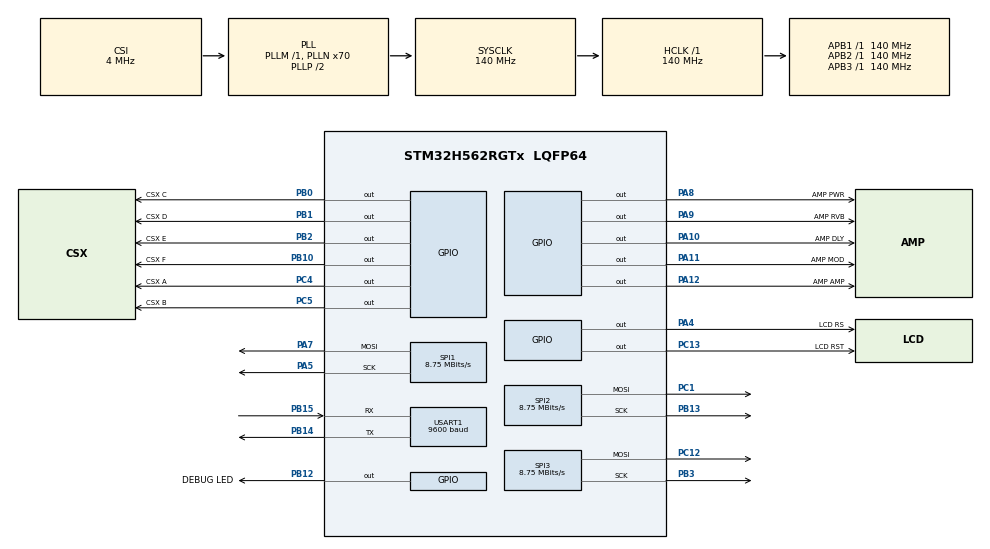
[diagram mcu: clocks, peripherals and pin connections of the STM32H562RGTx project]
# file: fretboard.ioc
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BOOTPATH.BootPathName=LEGACY
BOOTPATH.UserSelectedBootPath=LEGACY
CORTEX_M33_NS.userName=CORTEX_M33
Mcu.Family=STM32H5
Mcu.Name=STM32H562RGTx
Mcu.Package=LQFP64
NVIC.PriorityGroup=NVIC_PRIORITYGROUP_4
NVIC.TIM6_IRQn=true\:1\:0\:true\:false\:true\:true\:true\:true
NVIC.USART1_IRQn=true\:0\:0\:false\:false\:true\:true\:true\:true
PA10.GPIO_Label=AMP DLY
PA10.Signal=GPIO_Output
PA11.GPIO_Label=AMP MOD
PA11.Signal=GPIO_Output
PA12.GPIO_Label=AMP AMP
PA12.Signal=GPIO_Output
PA13(JTMS/SWDIO).Mode=Serial_Wire
PA13(JTMS/SWDIO).Signal=DEBUG_JTMS-SWDIO
PA14(JTCK/SWCLK).Mode=Serial_Wire
PA14(JTCK/SWCLK).Signal=DEBUG_JTCK-SWCLK
PA4.GPIO_Label=LCD RS
PA4.Signal=GPIO_Output
PA5.Mode=TX_Only_Simplex_Unidirect_Master
PA5.Signal=SPI1_SCK
PA7.Mode=TX_Only_Simplex_Unidirect_Master
PA7.Signal=SPI1_MOSI
PA8.GPIO_Label=AMP PWR
PA8.Signal=GPIO_Output
PA9.GPIO_Label=AMP RVB
PA9.Signal=GPIO_Output
PB0.GPIO_Label=CSX C
PB0.Signal=GPIO_Output
PB1.GPIO_Label=CSX D
PB1.Signal=GPIO_Output
PB10.GPIO_Label=CSX F
PB10.Signal=GPIO_Output
PB12.GPIO_Label=DEBUG LED
PB12.Signal=GPIO_Output
PB13.Mode=TX_Only_Simplex_Unidirect_Master
PB13.Signal=SPI2_SCK
PB14.Mode=Asynchronous
PB14.Signal=USART1_TX
PB15.Mode=Asynchronous
PB15.Signal=USART1_RX
PB2.GPIO_Label=CSX E
PB2.Signal=GPIO_Output
PB3(JTDO/TRACESWO).Mode=TX_Only_Simplex_Unidirect_Master
PB3(JTDO/TRACESWO).Signal=SPI3_SCK
PC1.Mode=TX_Only_Simplex_Unidirect_Master
PC1.Signal=SPI2_MOSI
PC12.Mode=TX_Only_Simplex_Unidirect_Master
PC12.Signal=SPI3_MOSI
PC13.GPIO_Label=LCD RST
PC13.Signal=GPIO_Output
PC4.GPIO_Label=CSX A
PC4.Signal=GPIO_Output
PC5.GPIO_Label=CSX B
PC5.Signal=GPIO_Output
ProjectManager.HeapSize=0x200
ProjectManager.StackSize=0x400
ProjectManager.TargetToolchain=STM32CubeIDE
RCC.ADCFreq_Value=140000000
RCC.AHBFreq_Value=140000000
RCC.APB1Freq_Value=140000000
RCC.APB1TimFreq_Value=140000000
RCC.APB2Freq_Value=140000000
RCC.APB2TimFreq_Value=140000000
RCC.APB3Freq_Value=140000000
RCC.CSI_VALUE=4000000
RCC.CortexFreq_Value=140000000
RCC.EPOD_VALUE=4000000
RCC.HCLKFreq_Value=140000000
RCC.HSE_VALUE=25000000
RCC.HSI48_VALUE=48000000
RCC.HSI_VALUE=64000000
RCC.LSE_VALUE=32768
RCC.LSIRC_VALUE=32000
RCC.PLL2FRACN=0
RCC.PLL3FRACN=0
RCC.PLLFRACN=0
RCC.PLLN=70
RCC.SYSCLKFreq_VALUE=140000000
RCC.SYSCLKSource=RCC_SYSCLKSOURCE_PLLCLK
RCC.USBFreq_Value=48000000
RCC.VCOOutputFreq_Value=280000000
SPI1.BaudRatePrescaler=SPI_BAUDRATEPRESCALER_16
SPI1.CalculateBaudRate=8.75 MBits/s
SPI1.DataSize=SPI_DATASIZE_8BIT
SPI1.Direction=SPI_DIRECTION_2LINES_TXONLY
SPI1.Mode=SPI_MODE_MASTER
SPI1.VirtualType=VM_MASTER
SPI2.BaudRatePrescaler=SPI_BAUDRATEPRESCALER_16
SPI2.CalculateBaudRate=8.75 MBits/s
SPI2.DataSize=SPI_DATASIZE_8BIT
SPI2.Direction=SPI_DIRECTION_2LINES_TXONLY
SPI2.Mode=SPI_MODE_MASTER
SPI2.VirtualType=VM_MASTER
SPI3.BaudRatePrescaler=SPI_BAUDRATEPRESCALER_16
SPI3.CalculateBaudRate=8.75 MBits/s
SPI3.DataSize=SPI_DATASIZE_8BIT
SPI3.Direction=SPI_DIRECTION_2LINES_TXONLY
SPI3.Mode=SPI_MODE_MASTER
SPI3.VirtualType=VM_MASTER
TIM6.PeriodNoDither=9
TIM6.Prescaler=24999
USART1.BaudRate=9600
USART1.OverrunDisableParam=ADVFEATURE_OVERRUN_ENABLE
USART1.VirtualMode-Asynchronous=VM_ASYNC
VP_BOOTPATH_VS_BOOTPATH.Mode=BP_Activate
VP_CORTEX_M33_NS_VS_Hclk.Mode=Hclk_Mode
VP_ICACHE_VS_ICACHE.Mode=DirectMappedCache
VP_MEMORYMAP_VS_MEMORYMAP.Mode=CurAppReg
VP_PWR_VS_DBSignals.Mode=DisableDeadBatterySignals
VP_PWR_VS_LPOM.Mode=PowerOptimisation
VP_PWR_VS_SECSignals.Mode=Security/Privilege
VP_TIM6_VS_ClockSourceINT.Mode=Enable_Timer
board=custom

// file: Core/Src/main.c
/* USER CODE BEGIN Header */
/**
  ******************************************************************************
  * @file           : main.c
  * @brief          : Main program body
  ******************************************************************************
  * @attention
  *
  * Copyright (c) 2024 STMicroelectronics.
  * All rights reserved.
  *
  * This software is licensed under terms that can be found in the LICENSE file
  * in the root directory of this software component.
  * If no LICENSE file comes with this software, it is provided AS-IS.
  *
  ******************************************************************************
  */
/* USER CODE END Header */
#include "main.h"

SPI_HandleTypeDef hspi1;
SPI_HandleTypeDef hspi2;
SPI_HandleTypeDef hspi3;

TIM_HandleTypeDef htim6;

UART_HandleTypeDef huart1;

void SystemClock_Config(void);
static void MX_GPIO_Init(void);
static void MX_SPI1_Init(void);
static void MX_USART1_UART_Init(void);
static void MX_SPI2_Init(void);
static void MX_TIM6_Init(void);
static void MX_SPI3_Init(void);
static void MX_ICACHE_Init(void);

int main(void)
{

  /* MCU Configuration--------------------------------------------------------*/

  /* Reset of all peripherals, Initializes the Flash interface and the Systick. */
  HAL_Init();

  /* Configure the system clock */
  SystemClock_Config();

  /* Initialize all configured peripherals */
  MX_GPIO_Init();
  MX_SPI1_Init();
  MX_USART1_UART_Init();
  MX_SPI2_Init();
  MX_TIM6_Init();
  MX_SPI3_Init();
  MX_ICACHE_Init();
  /* USER CODE BEGIN 2 */
  HAL_Post_Init();

  /* USER CODE END 2 */

  /* Infinite loop */
  while (1)
  {

  }
}

void SystemClock_Config(void)
{
  RCC_OscInitTypeDef RCC_OscInitStruct = {0};
  RCC_ClkInitTypeDef RCC_ClkInitStruct = {0};

  /** Configure the main internal regulator output voltage
  */
  __HAL_PWR_VOLTAGESCALING_CONFIG(PWR_REGULATOR_VOLTAGE_SCALE2);

  while(!__HAL_PWR_GET_FLAG(PWR_FLAG_VOSRDY)) {}

  /** Initializes the RCC Oscillators according to the specified parameters
  * in the RCC_OscInitTypeDef structure.
  */
  RCC_OscInitStruct.OscillatorType = RCC_OSCILLATORTYPE_CSI;
  RCC_OscInitStruct.CSIState = RCC_CSI_ON;
  RCC_OscInitStruct.CSICalibrationValue = RCC_CSICALIBRATION_DEFAULT;
  RCC_OscInitStruct.PLL.PLLState = RCC_PLL_ON;
  RCC_OscInitStruct.PLL.PLLSource = RCC_PLL1_SOURCE_CSI;
  RCC_OscInitStruct.PLL.PLLM = 1;
  RCC_OscInitStruct.PLL.PLLN = 70;
  RCC_OscInitStruct.PLL.PLLP = 2;
  RCC_OscInitStruct.PLL.PLLQ = 2;
  RCC_OscInitStruct.PLL.PLLR = 2;
  RCC_OscInitStruct.PLL.PLLRGE = RCC_PLL1_VCIRANGE_2;
  RCC_OscInitStruct.PLL.PLLVCOSEL = RCC_PLL1_VCORANGE_WIDE;
  RCC_OscInitStruct.PLL.PLLFRACN = 0;
  if (HAL_RCC_OscConfig(&RCC_OscInitStruct) != HAL_OK)
  {
    Error_Handler();
  }

  /** Initializes the CPU, AHB and APB buses clocks
  */
  RCC_ClkInitStruct.ClockType = RCC_CLOCKTYPE_HCLK|RCC_CLOCKTYPE_SYSCLK
                              |RCC_CLOCKTYPE_PCLK1|RCC_CLOCKTYPE_PCLK2
                              |RCC_CLOCKTYPE_PCLK3;
  RCC_ClkInitStruct.SYSCLKSource = RCC_SYSCLKSOURCE_PLLCLK;
  RCC_ClkInitStruct.AHBCLKDivider = RCC_SYSCLK_DIV1;
  RCC_ClkInitStruct.APB1CLKDivider = RCC_HCLK_DIV1;
  RCC_ClkInitStruct.APB2CLKDivider = RCC_HCLK_DIV1;
  RCC_ClkInitStruct.APB3CLKDivider = RCC_HCLK_DIV1;

  if (HAL_RCC_ClockConfig(&RCC_ClkInitStruct, FLASH_LATENCY_4) != HAL_OK)
  {
    Error_Handler();
  }

  /** Configure the programming delay
  */
  __HAL_FLASH_SET_PROGRAM_DELAY(FLASH_PROGRAMMING_DELAY_2);
}

static void MX_ICACHE_Init(void)
{

  /** Enable instruction cache in 1-way (direct mapped cache)
  */
  if (HAL_ICACHE_ConfigAssociativityMode(ICACHE_1WAY) != HAL_OK)
  {
    Error_Handler();
  }
  if (HAL_ICACHE_Enable() != HAL_OK)
  {
    Error_Handler();
  }

}

static void MX_SPI1_Init(void)
{

  /* SPI1 parameter configuration*/
  hspi1.Instance = SPI1;
  hspi1.Init.Mode = SPI_MODE_MASTER;
  hspi1.Init.Direction = SPI_DIRECTION_2LINES_TXONLY;
  hspi1.Init.DataSize = SPI_DATASIZE_8BIT;
  hspi1.Init.CLKPolarity = SPI_POLARITY_LOW;
  hspi1.Init.CLKPhase = SPI_PHASE_1EDGE;
  hspi1.Init.NSS = SPI_NSS_SOFT;
  hspi1.Init.BaudRatePrescaler = SPI_BAUDRATEPRESCALER_16;
  hspi1.Init.FirstBit = SPI_FIRSTBIT_MSB;
  hspi1.Init.TIMode = SPI_TIMODE_DISABLE;
  hspi1.Init.CRCCalculation = SPI_CRCCALCULATION_DISABLE;
  hspi1.Init.CRCPolynomial = 0x7;
  hspi1.Init.NSSPMode = SPI_NSS_PULSE_ENABLE;
  hspi1.Init.NSSPolarity = SPI_NSS_POLARITY_LOW;
  hspi1.Init.FifoThreshold = SPI_FIFO_THRESHOLD_01DATA;
  hspi1.Init.MasterSSIdleness = SPI_MASTER_SS_IDLENESS_00CYCLE;
  hspi1.Init.MasterInterDataIdleness = SPI_MASTER_INTERDATA_IDLENESS_00CYCLE;
  hspi1.Init.MasterReceiverAutoSusp = SPI_MASTER_RX_AUTOSUSP_DISABLE;
  hspi1.Init.MasterKeepIOState = SPI_MASTER_KEEP_IO_STATE_DISABLE;
  hspi1.Init.IOSwap = SPI_IO_SWAP_DISABLE;
  hspi1.Init.ReadyMasterManagement = SPI_RDY_MASTER_MANAGEMENT_INTERNALLY;
  hspi1.Init.ReadyPolarity = SPI_RDY_POLARITY_HIGH;
  if (HAL_SPI_Init(&hspi1) != HAL_OK)
  {
    Error_Handler();
  }

}

static void MX_SPI2_Init(void)
{

  /* SPI2 parameter configuration*/
  hspi2.Instance = SPI2;
  hspi2.Init.Mode = SPI_MODE_MASTER;
  hspi2.Init.Direction = SPI_DIRECTION_2LINES_TXONLY;
  hspi2.Init.DataSize = SPI_DATASIZE_8BIT;
  hspi2.Init.CLKPolarity = SPI_POLARITY_LOW;
  hspi2.Init.CLKPhase = SPI_PHASE_1EDGE;
  hspi2.Init.NSS = SPI_NSS_SOFT;
  hspi2.Init.BaudRatePrescaler = SPI_BAUDRATEPRESCALER_16;
  hspi2.Init.FirstBit = SPI_FIRSTBIT_MSB;
  hspi2.Init.TIMode = SPI_TIMODE_DISABLE;
  hspi2.Init.CRCCalculation = SPI_CRCCALCULATION_DISABLE;
  hspi2.Init.CRCPolynomial = 0x7;
  hspi2.Init.NSSPMode = SPI_NSS_PULSE_ENABLE;
  hspi2.Init.NSSPolarity = SPI_NSS_POLARITY_LOW;
  hspi2.Init.FifoThreshold = SPI_FIFO_THRESHOLD_01DATA;
  hspi2.Init.MasterSSIdleness = SPI_MASTER_SS_IDLENESS_00CYCLE;
  hspi2.Init.MasterInterDataIdleness = SPI_MASTER_INTERDATA_IDLENESS_00CYCLE;
  hspi2.Init.MasterReceiverAutoSusp = SPI_MASTER_RX_AUTOSUSP_DISABLE;
  hspi2.Init.MasterKeepIOState = SPI_MASTER_KEEP_IO_STATE_DISABLE;
  hspi2.Init.IOSwap = SPI_IO_SWAP_DISABLE;
  hspi2.Init.ReadyMasterManagement = SPI_RDY_MASTER_MANAGEMENT_INTERNALLY;
  hspi2.Init.ReadyPolarity = SPI_RDY_POLARITY_HIGH;
  if (HAL_SPI_Init(&hspi2) != HAL_OK)
  {
    Error_Handler();
  }

}

static void MX_SPI3_Init(void)
{

  /* SPI3 parameter configuration*/
  hspi3.Instance = SPI3;
  hspi3.Init.Mode = SPI_MODE_MASTER;
  hspi3.Init.Direction = SPI_DIRECTION_2LINES_TXONLY;
  hspi3.Init.DataSize = SPI_DATASIZE_8BIT;
  hspi3.Init.CLKPolarity = SPI_POLARITY_LOW;
  hspi3.Init.CLKPhase = SPI_PHASE_1EDGE;
  hspi3.Init.NSS = SPI_NSS_SOFT;
  hspi3.Init.BaudRatePrescaler = SPI_BAUDRATEPRESCALER_16;
  hspi3.Init.FirstBit = SPI_FIRSTBIT_MSB;
  hspi3.Init.TIMode = SPI_TIMODE_DISABLE;
  hspi3.Init.CRCCalculation = SPI_CRCCALCULATION_DISABLE;
  hspi3.Init.CRCPolynomial = 0x7;
  hspi3.Init.NSSPMode = SPI_NSS_PULSE_ENABLE;
  hspi3.Init.NSSPolarity = SPI_NSS_POLARITY_LOW;
  hspi3.Init.FifoThreshold = SPI_FIFO_THRESHOLD_01DATA;
  hspi3.Init.MasterSSIdleness = SPI_MASTER_SS_IDLENESS_00CYCLE;
  hspi3.Init.MasterInterDataIdleness = SPI_MASTER_INTERDATA_IDLENESS_00CYCLE;
  hspi3.Init.MasterReceiverAutoSusp = SPI_MASTER_RX_AUTOSUSP_DISABLE;
  hspi3.Init.MasterKeepIOState = SPI_MASTER_KEEP_IO_STATE_DISABLE;
  hspi3.Init.IOSwap = SPI_IO_SWAP_DISABLE;
  hspi3.Init.ReadyMasterManagement = SPI_RDY_MASTER_MANAGEMENT_INTERNALLY;
  hspi3.Init.ReadyPolarity = SPI_RDY_POLARITY_HIGH;
  if (HAL_SPI_Init(&hspi3) != HAL_OK)
  {
    Error_Handler();
  }

}

static void MX_TIM6_Init(void)
{

  TIM_MasterConfigTypeDef sMasterConfig = {0};

  htim6.Instance = TIM6;
  htim6.Init.Prescaler = 24999;
  htim6.Init.CounterMode = TIM_COUNTERMODE_UP;
  htim6.Init.Period = 9;
  htim6.Init.AutoReloadPreload = TIM_AUTORELOAD_PRELOAD_DISABLE;
  if (HAL_TIM_Base_Init(&htim6) != HAL_OK)
  {
    Error_Handler();
  }
  sMasterConfig.MasterOutputTrigger = TIM_TRGO_RESET;
  sMasterConfig.MasterSlaveMode = TIM_MASTERSLAVEMODE_DISABLE;
  if (HAL_TIMEx_MasterConfigSynchronization(&htim6, &sMasterConfig) != HAL_OK)
  {
    Error_Handler();
  }

}

static void MX_USART1_UART_Init(void)
{

  huart1.Instance = USART1;
  huart1.Init.BaudRate = 9600;
  huart1.Init.WordLength = UART_WORDLENGTH_8B;
  huart1.Init.StopBits = UART_STOPBITS_1;
  huart1.Init.Parity = UART_PARITY_NONE;
  huart1.Init.Mode = UART_MODE_TX_RX;
  huart1.Init.HwFlowCtl = UART_HWCONTROL_NONE;
  huart1.Init.OverSampling = UART_OVERSAMPLING_16;
  huart1.Init.OneBitSampling = UART_ONE_BIT_SAMPLE_DISABLE;
  huart1.Init.ClockPrescaler = UART_PRESCALER_DIV1;
  huart1.AdvancedInit.AdvFeatureInit = UART_ADVFEATURE_NO_INIT;
  if (HAL_UART_Init(&huart1) != HAL_OK)
  {
    Error_Handler();
  }
  if (HAL_UARTEx_SetTxFifoThreshold(&huart1, UART_TXFIFO_THRESHOLD_1_8) != HAL_OK)
  {
    Error_Handler();
  }
  if (HAL_UARTEx_SetRxFifoThreshold(&huart1, UART_RXFIFO_THRESHOLD_1_8) != HAL_OK)
  {
    Error_Handler();
  }
  if (HAL_UARTEx_DisableFifoMode(&huart1) != HAL_OK)
  {
    Error_Handler();
  }

}

static void MX_GPIO_Init(void)
{
  GPIO_InitTypeDef GPIO_InitStruct = {0};

  /* GPIO Ports Clock Enable */
  __HAL_RCC_GPIOC_CLK_ENABLE();
  __HAL_RCC_GPIOA_CLK_ENABLE();
  __HAL_RCC_GPIOB_CLK_ENABLE();

  /*Configure GPIO pin Output Level */
  HAL_GPIO_WritePin(GPIOC, LCD_RST_Pin|CSX_A_Pin|CSX_B_Pin, GPIO_PIN_RESET);

  /*Configure GPIO pin Output Level */
  HAL_GPIO_WritePin(GPIOA, LCD_RS_Pin|AMP_PWR_Pin|AMP_RVB_Pin|AMP_DLY_Pin
                          |AMP_MOD_Pin|AMP_AMP_Pin, GPIO_PIN_RESET);

  /*Configure GPIO pin Output Level */
  HAL_GPIO_WritePin(GPIOB, CSX_C_Pin|CSX_D_Pin|CSX_E_Pin|CSX_F_Pin
                          |DEBUG_LED_Pin, GPIO_PIN_RESET);

  /*Configure GPIO pins : LCD_RST_Pin CSX_A_Pin CSX_B_Pin */
  GPIO_InitStruct.Pin = LCD_RST_Pin|CSX_A_Pin|CSX_B_Pin;
  GPIO_InitStruct.Mode = GPIO_MODE_OUTPUT_PP;
  GPIO_InitStruct.Pull = GPIO_NOPULL;
  GPIO_InitStruct.Speed = GPIO_SPEED_FREQ_LOW;
  HAL_GPIO_Init(GPIOC, &GPIO_InitStruct);

  /*Configure GPIO pins : LCD_RS_Pin AMP_PWR_Pin AMP_RVB_Pin AMP_DLY_Pin
                           AMP_MOD_Pin AMP_AMP_Pin */
  GPIO_InitStruct.Pin = LCD_RS_Pin|AMP_PWR_Pin|AMP_RVB_Pin|AMP_DLY_Pin
                          |AMP_MOD_Pin|AMP_AMP_Pin;
  GPIO_InitStruct.Mode = GPIO_MODE_OUTPUT_PP;
  GPIO_InitStruct.Pull = GPIO_NOPULL;
  GPIO_InitStruct.Speed = GPIO_SPEED_FREQ_LOW;
  HAL_GPIO_Init(GPIOA, &GPIO_InitStruct);

  /*Configure GPIO pins : CSX_C_Pin CSX_D_Pin CSX_E_Pin CSX_F_Pin
                           DEBUG_LED_Pin */
  GPIO_InitStruct.Pin = CSX_C_Pin|CSX_D_Pin|CSX_E_Pin|CSX_F_Pin
                          |DEBUG_LED_Pin;
  GPIO_InitStruct.Mode = GPIO_MODE_OUTPUT_PP;
  GPIO_InitStruct.Pull = GPIO_NOPULL;
  GPIO_InitStruct.Speed = GPIO_SPEED_FREQ_LOW;
  HAL_GPIO_Init(GPIOB, &GPIO_InitStruct);

}

void Error_Handler(void)
{
  __disable_irq();
  while (1)
  {
  }
}
